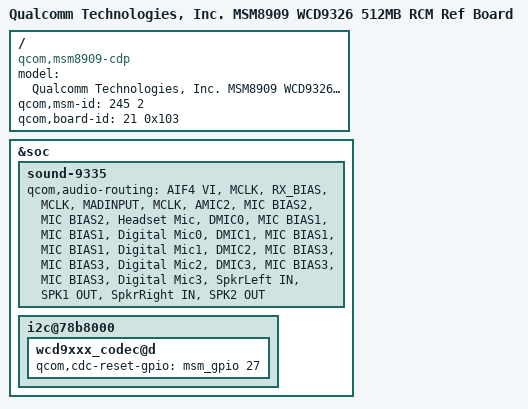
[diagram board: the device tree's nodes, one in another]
/*
 * Copyright (c) 2016-2017, The Linux Foundation. All rights reserved.
 *
 * This program is free software; you can redistribute it and/or modify
 * it under the terms of the GNU General Public License version 2 and
 * only version 2 as published by the Free Software Foundation.
 *
 * This program is distributed in the hope that it will be useful,
 * but WITHOUT ANY WARRANTY; without even the implied warranty of
 * MERCHANTABILITY or FITNESS FOR A PARTICULAR PURPOSE.  See the
 * GNU General Public License for more details.
 */

/dts-v1/;

#include "msm8909-cdp.dtsi"
#include "msm8909-pm8916.dtsi"
#include "msm8909-pm8916-cdp.dtsi"
#include "apq8009-audio-external_codec.dtsi"

/ {
	model = "Qualcomm Technologies, Inc. MSM8909 WCD9326 512MB \
						RCM Ref Board";
	compatible = "qcom,msm8909-cdp", "qcom,msm8909", "qcom,cdp";
	qcom,msm-id = <245 2>;
	qcom,board-id= <21 0x103>;
};

&soc {
	sound-9335 {
		qcom,audio-routing =
			"AIF4 VI", "MCLK",
			"RX_BIAS", "MCLK",
			"MADINPUT", "MCLK",
			"AMIC2", "MIC BIAS2",
			"MIC BIAS2", "Headset Mic",
			"DMIC0", "MIC BIAS1",
			"MIC BIAS1", "Digital Mic0",
			"DMIC1", "MIC BIAS1",
			"MIC BIAS1", "Digital Mic1",
			"DMIC2", "MIC BIAS3",
			"MIC BIAS3", "Digital Mic2",
			"DMIC3", "MIC BIAS3",
			"MIC BIAS3", "Digital Mic3",
			"SpkrLeft IN", "SPK1 OUT",
			"SpkrRight IN", "SPK2 OUT";
	};

	i2c@78b8000 {
		wcd9xxx_codec@d {
			qcom,cdc-reset-gpio = <&msm_gpio 27 0>;
		};
	};
};

